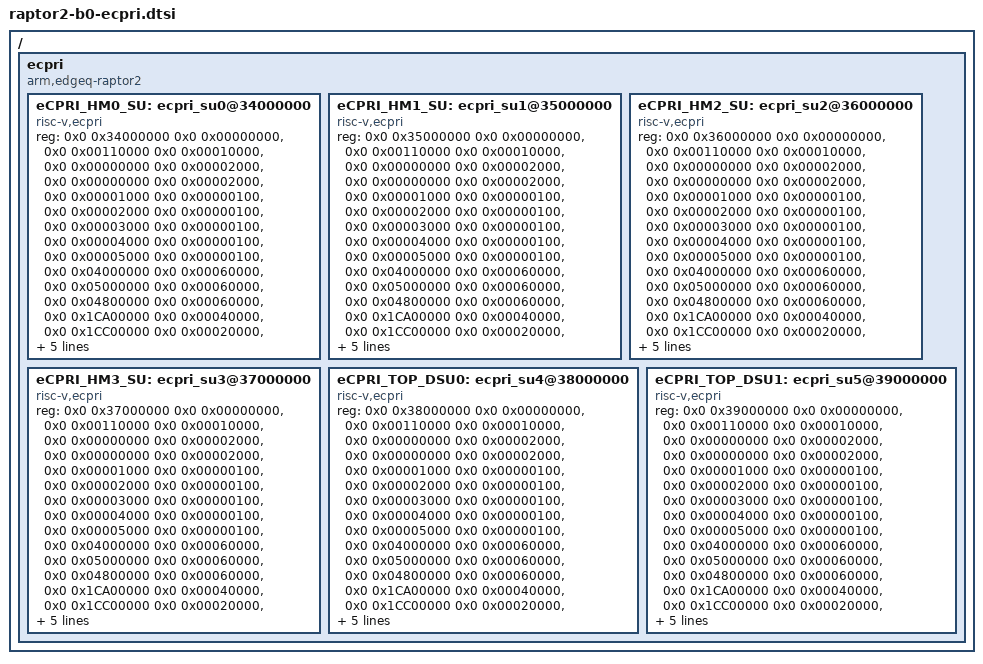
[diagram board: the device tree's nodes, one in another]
// SPDX-License-Identifier: GPL-2.0
/*
 * EdgeQ Inc.
 *
 * EdgeQ Raptor2 ECPRI DTS
 */

/ {
	ecpri {
		compatible = "arm,edgeq-raptor2";
		#address-cells = <2>;
		#size-cells = <2>;

		eCPRI_HM0_SU: ecpri_su0@34000000 {
			compatible = "risc-v,ecpri";
			device_type = "su";
			#address-cells = <2>;
			#size-cells = <2>;
			ranges;
			reg =	<0x0 0x34000000 0x0 0x00000000>,
				<0x0 0x00110000 0x0 0x00010000>,
				<0x0 0x00000000 0x0 0x00002000>,
				<0x0 0x00000000 0x0 0x00002000>,
				<0x0 0x00001000 0x0 0x00000100>,
				<0x0 0x00002000 0x0 0x00000100>,
				<0x0 0x00003000 0x0 0x00000100>,
				<0x0 0x00004000 0x0 0x00000100>,
				<0x0 0x00005000 0x0 0x00000100>,
				<0x0 0x04000000 0x0 0x00060000>,
				<0x0 0x05000000 0x0 0x00060000>,
				<0x0 0x04800000 0x0 0x00060000>,
				<0x0 0x1CA00000 0x0 0x00040000>,
				<0x0 0x1CC00000 0x0 0x00020000>,
				<0x0 0x00000000 0x0 0x00004000>,
				<0x0 0x00080000 0x0 0x00008000>;
			reg-names = "sudev_base", "cpu", "d-cache", "i-cache", "suinfo_offset",
				"suconf_offset", "suau_offset", "sustats_offset", "sudbg_offset",
				"lmem_addr_local_wb", "lmem_addr_local_unc", "lmem_addr_local_wt",
				"lmem_e1", "lmem_e1_b2", "ilmoffs", "dlmoffs";
			enable-method = "reset-vector";
			sudev = <&SUDEV>;
			sumem = <&SUMEM>;
			status = "okay";
		};

		eCPRI_HM1_SU: ecpri_su1@35000000 {
			compatible = "risc-v,ecpri";
			device_type = "su";
			#address-cells = <2>;
			#size-cells = <2>;
			ranges;
			reg =	<0x0 0x35000000 0x0 0x00000000>,
				<0x0 0x00110000 0x0 0x00010000>,
				<0x0 0x00000000 0x0 0x00002000>,
				<0x0 0x00000000 0x0 0x00002000>,
				<0x0 0x00001000 0x0 0x00000100>,
				<0x0 0x00002000 0x0 0x00000100>,
				<0x0 0x00003000 0x0 0x00000100>,
				<0x0 0x00004000 0x0 0x00000100>,
				<0x0 0x00005000 0x0 0x00000100>,
				<0x0 0x04000000 0x0 0x00060000>,
				<0x0 0x05000000 0x0 0x00060000>,
				<0x0 0x04800000 0x0 0x00060000>,
				<0x0 0x1CA00000 0x0 0x00040000>,
				<0x0 0x1CC00000 0x0 0x00020000>,
				<0x0 0x00000000 0x0 0x00004000>,
				<0x0 0x00080000 0x0 0x00008000>;
			reg-names = "sudev_base", "cpu", "d-cache", "i-cache", "suinfo_offset",
				"suconf_offset", "suau_offset", "sustats_offset", "sudbg_offset",
				"lmem_addr_local_wb", "lmem_addr_local_unc", "lmem_addr_local_wt",
				"lmem_e1", "lmem_e1_b2", "ilmoffs", "dlmoffs";
			enable-method = "reset-vector";
			sudev = <&SUDEV>;
			sumem = <&SUMEM>;
			status = "okay";
		};

		eCPRI_HM2_SU: ecpri_su2@36000000 {
			compatible = "risc-v,ecpri";
			device_type = "su";
			#address-cells = <2>;
			#size-cells = <2>;
			ranges;
			reg =	<0x0 0x36000000 0x0 0x00000000>,
				<0x0 0x00110000 0x0 0x00010000>,
				<0x0 0x00000000 0x0 0x00002000>,
				<0x0 0x00000000 0x0 0x00002000>,
				<0x0 0x00001000 0x0 0x00000100>,
				<0x0 0x00002000 0x0 0x00000100>,
				<0x0 0x00003000 0x0 0x00000100>,
				<0x0 0x00004000 0x0 0x00000100>,
				<0x0 0x00005000 0x0 0x00000100>,
				<0x0 0x04000000 0x0 0x00060000>,
				<0x0 0x05000000 0x0 0x00060000>,
				<0x0 0x04800000 0x0 0x00060000>,
				<0x0 0x1CA00000 0x0 0x00040000>,
				<0x0 0x1CC00000 0x0 0x00020000>,
				<0x0 0x00000000 0x0 0x00004000>,
				<0x0 0x00080000 0x0 0x00008000>;
			reg-names = "sudev_base", "cpu", "d-cache", "i-cache", "suinfo_offset",
				"suconf_offset", "suau_offset", "sustats_offset", "sudbg_offset",
				"lmem_addr_local_wb", "lmem_addr_local_unc", "lmem_addr_local_wt",
				"lmem_e1", "lmem_e1_b2", "ilmoffs", "dlmoffs";
			enable-method = "reset-vector";
			sudev = <&SUDEV>;
			sumem = <&SUMEM>;
			status = "okay";
		};

		eCPRI_HM3_SU: ecpri_su3@37000000 {
			compatible = "risc-v,ecpri";
			device_type = "su";
			#address-cells = <2>;
			#size-cells = <2>;
			ranges;
			reg =	<0x0 0x37000000 0x0 0x00000000>,
				<0x0 0x00110000 0x0 0x00010000>,
				<0x0 0x00000000 0x0 0x00002000>,
				<0x0 0x00000000 0x0 0x00002000>,
				<0x0 0x00001000 0x0 0x00000100>,
				<0x0 0x00002000 0x0 0x00000100>,
				<0x0 0x00003000 0x0 0x00000100>,
				<0x0 0x00004000 0x0 0x00000100>,
				<0x0 0x00005000 0x0 0x00000100>,
				<0x0 0x04000000 0x0 0x00060000>,
				<0x0 0x05000000 0x0 0x00060000>,
				<0x0 0x04800000 0x0 0x00060000>,
				<0x0 0x1CA00000 0x0 0x00040000>,
				<0x0 0x1CC00000 0x0 0x00020000>,
				<0x0 0x00000000 0x0 0x00004000>,
				<0x0 0x00080000 0x0 0x00008000>;
			reg-names = "sudev_base", "cpu", "d-cache", "i-cache", "suinfo_offset",
				"suconf_offset", "suau_offset", "sustats_offset", "sudbg_offset",
				"lmem_addr_local_wb", "lmem_addr_local_unc", "lmem_addr_local_wt",
				"lmem_e1", "lmem_e1_b2", "ilmoffs", "dlmoffs";
			enable-method = "reset-vector";
			sudev = <&SUDEV>;
			sumem = <&SUMEM>;
			status = "okay";
		};

		eCPRI_TOP_DSU0: ecpri_su4@38000000 {
			compatible = "risc-v,ecpri";
			device_type = "su";
			#address-cells = <2>;
			#size-cells = <2>;
			ranges;
			reg =	<0x0 0x38000000 0x0 0x00000000>,
				<0x0 0x00110000 0x0 0x00010000>,
				<0x0 0x00000000 0x0 0x00002000>,
				<0x0 0x00000000 0x0 0x00002000>,
				<0x0 0x00001000 0x0 0x00000100>,
				<0x0 0x00002000 0x0 0x00000100>,
				<0x0 0x00003000 0x0 0x00000100>,
				<0x0 0x00004000 0x0 0x00000100>,
				<0x0 0x00005000 0x0 0x00000100>,
				<0x0 0x04000000 0x0 0x00060000>,
				<0x0 0x05000000 0x0 0x00060000>,
				<0x0 0x04800000 0x0 0x00060000>,
				<0x0 0x1CA00000 0x0 0x00040000>,
				<0x0 0x1CC00000 0x0 0x00020000>,
				<0x0 0x00000000 0x0 0x00010000>,
				<0x0 0x00080000 0x0 0x00008000>;
			reg-names = "sudev_base", "cpu", "d-cache", "i-cache", "suinfo_offset",
				"suconf_offset", "suau_offset", "sustats_offset", "sudbg_offset",
				"lmem_addr_local_wb", "lmem_addr_local_unc", "lmem_addr_local_wt",
				"lmem_e1", "lmem_e1_b2", "ilmoffs", "dlmoffs";
			enable-method = "reset-vector";
			sudev = <&SUDEV>;
			sumem = <&SUMEM>;
			status = "okay";
		};

		eCPRI_TOP_DSU1: ecpri_su5@39000000 {
			compatible = "risc-v,ecpri";
			device_type = "su";
			#address-cells = <2>;
			#size-cells = <2>;
			ranges;
			reg =	<0x0 0x39000000 0x0 0x00000000>,
				<0x0 0x00110000 0x0 0x00010000>,
				<0x0 0x00000000 0x0 0x00002000>,
				<0x0 0x00000000 0x0 0x00002000>,
				<0x0 0x00001000 0x0 0x00000100>,
				<0x0 0x00002000 0x0 0x00000100>,
				<0x0 0x00003000 0x0 0x00000100>,
				<0x0 0x00004000 0x0 0x00000100>,
				<0x0 0x00005000 0x0 0x00000100>,
				<0x0 0x04000000 0x0 0x00060000>,
				<0x0 0x05000000 0x0 0x00060000>,
				<0x0 0x04800000 0x0 0x00060000>,
				<0x0 0x1CA00000 0x0 0x00040000>,
				<0x0 0x1CC00000 0x0 0x00020000>,
				<0x0 0x00000000 0x0 0x00010000>,
				<0x0 0x00080000 0x0 0x00008000>;
			reg-names = "sudev_base", "cpu", "d-cache", "i-cache", "suinfo_offset",
				"suconf_offset", "suau_offset", "sustats_offset", "sudbg_offset",
				"lmem_addr_local_wb", "lmem_addr_local_unc", "lmem_addr_local_wt",
				"lmem_e1", "lmem_e1_b2", "ilmoffs", "dlmoffs";
			enable-method = "reset-vector";
			sudev = <&SUDEV>;
			sumem = <&SUMEM>;
			status = "okay";
		};
	};
};
